# BlueNRG_LPF register map
File version: 1.0
CPU: CM0+ r0p0, little endian, no MPU, no FPU, 2 interrupt priority bits
Registers are 32-bit, read-write, reset 0x0 unless marked. A register's access mark holds for its fields unless they carry their own. Offsets are from the block's base; [hi:lo] are bit positions; {n}, {i} and the like mark numbered series.

## DMAMUX — Direct memory access Multiplexer
Base 0x48800000
{0x0+4i} C{i}CR (i=0..7) — DMA Multiplexer Channel {i} Control register
  [4:0] DMAREQ_ID — DMA Request ID

## FLASH
Base 0x40001000
0x00 COMMAND
  [7:0] COMMAND
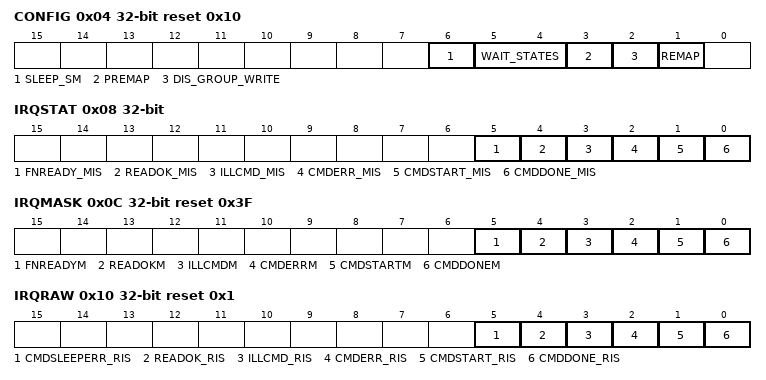
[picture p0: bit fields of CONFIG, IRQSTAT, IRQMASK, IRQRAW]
0x04 CONFIG reset 0x10
  [6] SLEEP_SM, [5:4] WAIT_STATES, [3] PREMAP, [2] DIS_GROUP_WRITE, [1] REMAP
0x08 IRQSTAT
  [5] FNREADY_MIS, [4] READOK_MIS, [3] ILLCMD_MIS, [2] CMDERR_MIS, [1] CMDSTART_MIS, [0] CMDDONE_MIS
0x0C IRQMASK reset 0x3F
  [5] FNREADYM, [4] READOKM, [3] ILLCMDM, [2] CMDERRM, [1] CMDSTARTM, [0] CMDDONEM
0x10 IRQRAW reset 0x1
  [5] CMDSLEEPERR_RIS, [4] READOK_RIS, [3] ILLCMD_RIS, [2] CMDERR_RIS, [1] CMDSTART_RIS, [0] CMDDONE_RIS
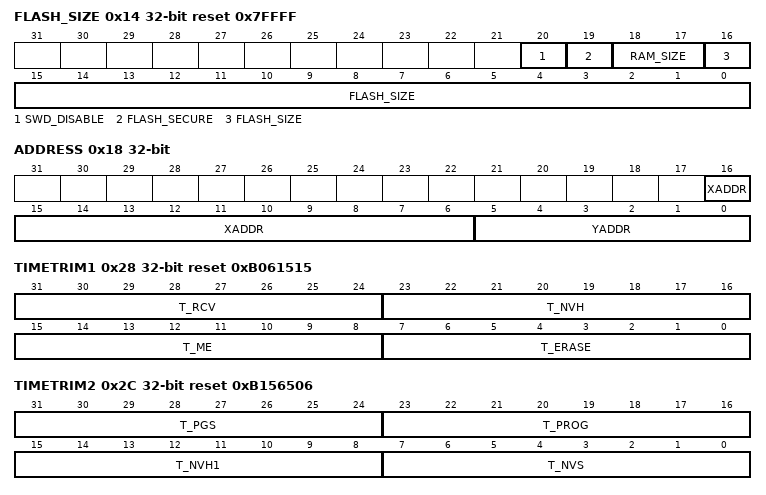
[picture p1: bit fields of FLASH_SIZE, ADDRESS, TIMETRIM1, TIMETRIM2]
0x14 FLASH_SIZE ro reset 0x7FFFF — SIZE register
  [20] SWD_DISABLE, [19] FLASH_SECURE, [18:17] RAM_SIZE, [16:0] FLASH_SIZE
0x18 ADDRESS
  [16:6] XADDR, [5:0] YADDR
0x24 LFSRVAL ro reset 0xFFFFFFFF
0x28 TIMETRIM1 reset 0xB061515
  [31:24] T_RCV, [23:16] T_NVH, [15:8] T_ME, [7:0] T_ERASE
0x2C TIMETRIM2 reset 0xB156506
  [31:24] T_PGS, [23:16] T_PROG, [15:8] T_NVH1, [7:0] T_NVS
0x30 TIMETRIM3 reset 0x11
  [7:0] T_WK
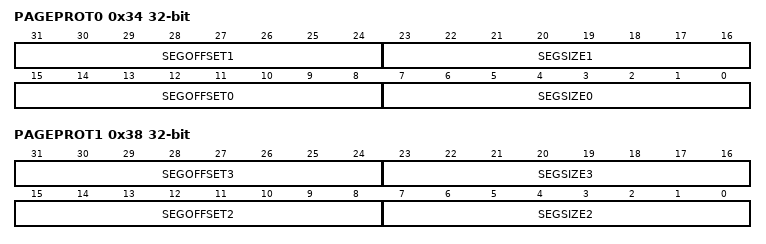
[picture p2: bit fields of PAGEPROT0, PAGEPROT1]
0x34 PAGEPROT0
  [31:24] SEGOFFSET1, [23:16] SEGSIZE1, [15:8] SEGOFFSET0, [7:0] SEGSIZE0
0x38 PAGEPROT1
  [31:24] SEGOFFSET3, [23:16] SEGSIZE3, [15:8] SEGOFFSET2, [7:0] SEGSIZE2
{0x40+4i} DATA{i} reset 0xFFFFFFFF (i=0..3)

## GPIOA — General-purpose I/Os
Base 0x48000000
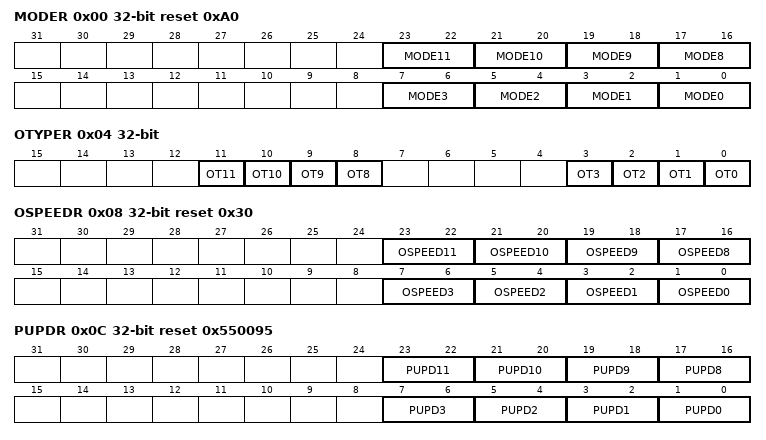
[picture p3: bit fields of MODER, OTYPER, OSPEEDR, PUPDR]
0x00 MODER reset 0xA0 — GPIO port mode register
  [2n+1:2n] MODE{n} (n=8..11) — Port A configuration bit {n}
  [2n+1:2n] MODE{n} (n=0..3) — Port A configuration bit {n}
0x04 OTYPER — GPIO port output type register
  [n] OT{n} (n=8..11) — Port A configuration bit {n}
  [n] OT{n} (n=0..3) — Port A configuration bit {n}
0x08 OSPEEDR reset 0x30 — GPIO port output speed register
  [2n+1:2n] OSPEED{n} (n=8..11) — Port A configuration bit {n}
  [2n+1:2n] OSPEED{n} (n=0..3) — Port A configuration bit {n}
0x0C PUPDR reset 0x550095 — GPIO port pull-up/pull-down register
  [2n+1:2n] PUPD{n} (n=8..11) — Port A configuration bit {n}
  [2n+1:2n] PUPD{n} (n=0..3) — Port A configuration bit {n}
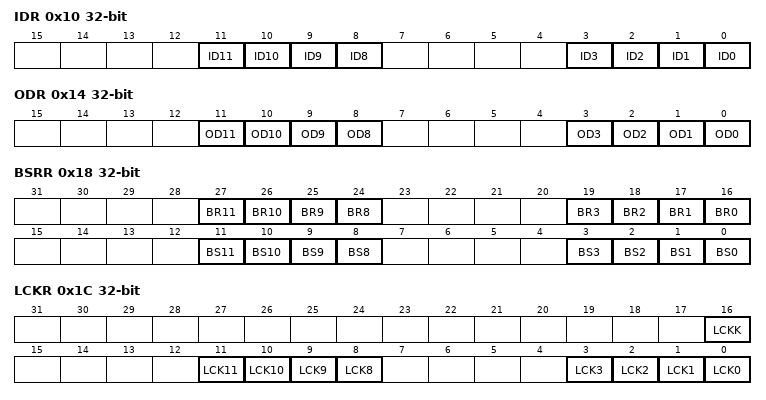
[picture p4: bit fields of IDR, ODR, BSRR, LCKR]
0x10 IDR ro — GPIO port input data register
  [n] ID{n} (n=8..11) — Port A input data bit {n}
  [n] ID{n} (n=0..3) — Port A input data bit {n}
0x14 ODR — GPIO port output data register
  [n] OD{n} (n=8..11) — Port A output data bit {n}
  [n] OD{n} (n=0..3) — Port A output data bit {n}
0x18 BSRR wo — GPIO port A bit set/reset register
  [n+16] BR{n} (n=8..11) — Port A reset bit {n}
  [19] BR3 — Port A reset bit 3
  [18] BR2 — Port A reset bit 2
  [17] BR1 — Port A reset bit 1
  [16] BR0 — Port A set bit 0
  [n] BS{n} (n=8..11) — Port A set bit {n}
  [n] BS{n} (n=0..3) — Port A set bit {n}
0x1C LCKR — GPIO port configuration lock register
  [16] LCKK — Lock key. This bit can be read any time. It can only be modified using the lock key write sequence.
  [n] LCK{n} (n=8..11) — Port A lock bit {n}
  [n] LCK{n} (n=0..3) — Port A lock bit {n}
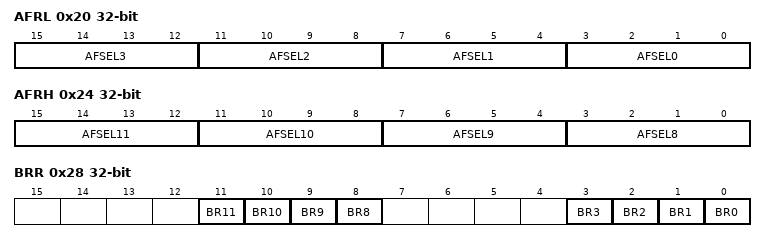
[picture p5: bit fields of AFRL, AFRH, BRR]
0x20 AFRL — GPIO alternate function low register
  [4n+3:4n] AFSEL{n} (n=0..3) — Alternate function selection for port A bit {n}
0x24 AFRH — GPIO alternate function high register
  [4n-29:4n-32] AFSEL{n} (n=8..11) — Alternate function selection for port A bit {n}
0x28 BRR wo — GPIO alternate function high register
  [n] BR{n} (n=8..11) — Port A output data bit {n}
  [n] BR{n} (n=0..3) — Port A output data bit {n}

## GPIOB — General-purpose I/Os
Base 0x48100000
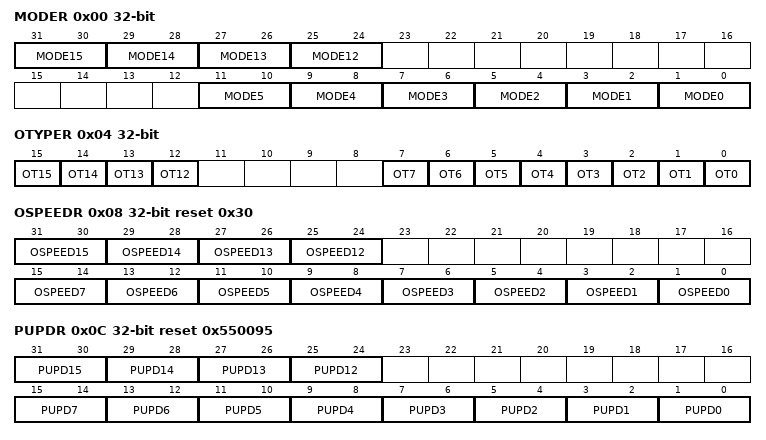
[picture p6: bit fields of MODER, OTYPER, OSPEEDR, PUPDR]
0x00 MODER — GPIO port mode register
  [2n+1:2n] MODE{n} (n=12..15) — Port B configuration bit {n}
  [2n+1:2n] MODE{n} (n=0..5) — Port B configuration bit {n}
0x04 OTYPER — GPIO port output type register
  [n] OT{n} (n=12..15) — Port B configuration bit {n}
  [n] OT{n} (n=0..7) — Port B configuration bit {n}
0x08 OSPEEDR reset 0x30 — GPIO port output speed register
  [2n+1:2n] OSPEED{n} (n=12..15) — Port B configuration bit {n}
  [2n+1:2n] OSPEED{n} (n=0..7) — Port B configuration bit {n}
0x0C PUPDR reset 0x550095 — GPIO port pull-up/pull-down register
  [2n+1:2n] PUPD{n} (n=12..15) — Port B configuration bit {n}
  [15:14] PUPD7 — Port B configuration bit7
  [2n+1:2n] PUPD{n} (n=0..6) — Port B configuration bit {n}
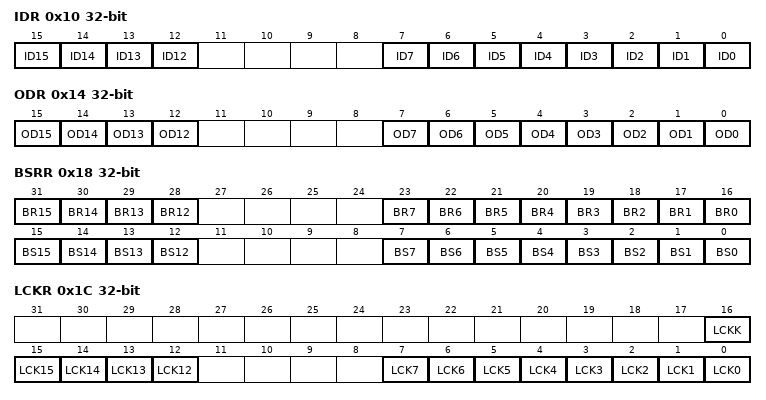
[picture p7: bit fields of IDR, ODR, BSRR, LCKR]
0x10 IDR ro — GPIO port input data register
  [n] ID{n} (n=12..15) — Port B input data bit {n}
  [n] ID{n} (n=0..7) — Port B input data bit {n}
0x14 ODR — GPIO port output data register
  [n] OD{n} (n=12..15) — Port B output data bit {n}
  [n] OD{n} (n=0..7) — Port B output data bit {n}
0x18 BSRR wo — GPIO port A bit set/reset register
  [n+16] BR{n} (n=12..15) — Port B reset bit {n}
  [n+16] BR{n} (n=1..7) — Port B reset bit {n}
  [16] BR0 — Port B set bit 0
  [n] BS{n} (n=12..15) — Port B set bit {n}
  [n] BS{n} (n=0..7) — Port B set bit {n}
0x1C LCKR — GPIO port configuration lock register
  [16] LCKK — Lock key. This bit can be read any time. It can only be modified using the lock key write sequence.
  [n] LCK{n} (n=12..15) — Port B lock bit {n}
  [n] LCK{n} (n=0..7) — Port B lock bit {n}
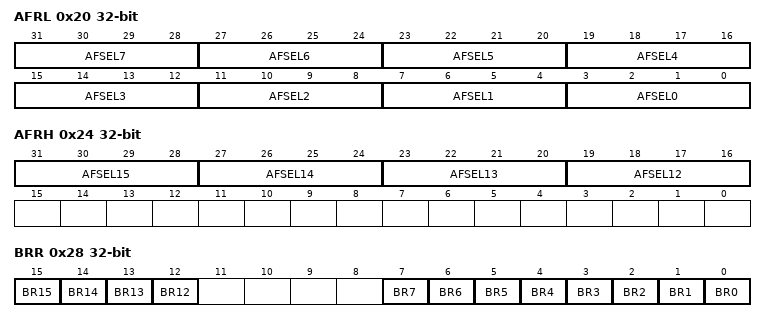
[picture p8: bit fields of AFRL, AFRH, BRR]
0x20 AFRL — GPIO alternate function low register
  [4n+3:4n] AFSEL{n} (n=0..7) — Alternate function selection for port A bit {n}
0x24 AFRH — GPIO alternate function high register
  [4n-29:4n-32] AFSEL{n} (n=12..15) — Alternate function selection for port A bit {n}
0x28 BRR wo — GPIO alternate function high register
  [n] BR{n} (n=12..15) — Port B output data bit {n}
  [n] BR{n} (n=0..7) — Port B output data bit {n}
